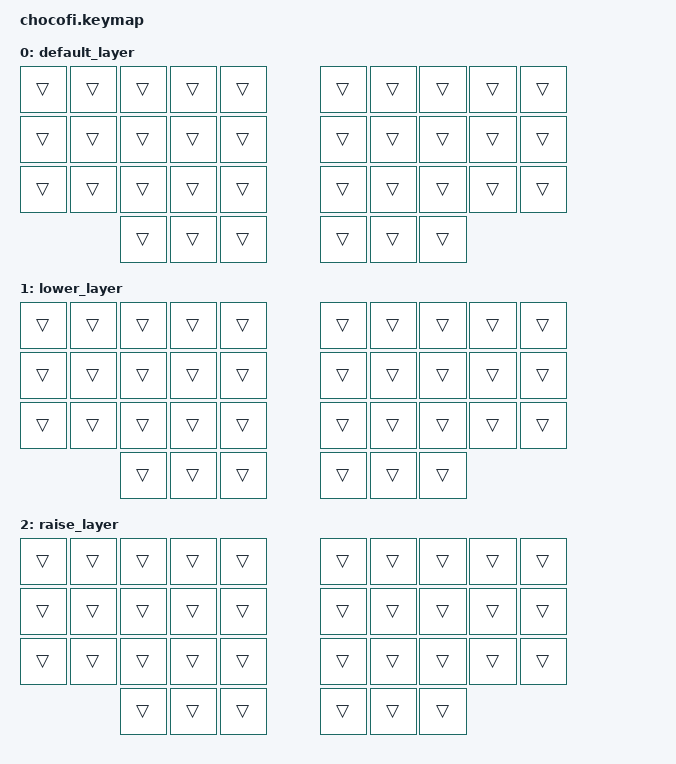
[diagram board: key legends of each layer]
#include <behaviors.dtsi>
#include <dt-bindings/zmk/keys.h>
#include <dt-bindings/zmk/bt.h>

/ {
    keymap {
        compatible = "zmk,keymap";

        default_layer {
            bindings = 
                &trans &trans &trans &trans &trans    &trans &trans &trans &trans &trans
                &trans &trans &trans &trans &trans    &trans &trans &trans &trans &trans
                &trans &trans &trans &trans &trans    &trans &trans &trans &trans &trans
                              &trans &trans &trans    &trans &trans &trans
            >;
        };

        lower_layer {
            bindings = 
                &trans &trans &trans &trans &trans    &trans &trans &trans &trans &trans
                &trans &trans &trans &trans &trans    &trans &trans &trans &trans &trans
                &trans &trans &trans &trans &trans    &trans &trans &trans &trans &trans
                              &trans &trans &trans    &trans &trans &trans
            >;
        };

        raise_layer {
            bindings = 
                &trans &trans &trans &trans &trans    &trans &trans &trans &trans &trans
                &trans &trans &trans &trans &trans    &trans &trans &trans &trans &trans
                &trans &trans &trans &trans &trans    &trans &trans &trans &trans &trans
                              &trans &trans &trans    &trans &trans &trans
            >;
        };
    };
};
